# PRU_ICSS_0_MII_MDIO_local register map
Vendor: Texas Instruments
Peripheral module from a debugger description file (folder 66AK2G0x_66AK2G1x).
Registers are 32-bit, access not given, reset 0x0 unless marked. A register's access mark holds for its fields unless they carry their own. Offsets are as the file gives them; lines under a group give offsets from that group; [hi:lo] are bit positions; {n}, {i} and the like mark numbered series; 'fields as' and 'values as' point back to an identical list; <NAME> marks a mode.

## PRU_ICSS_0_MII_MDIO
0x00 PRUSS_MII_MDIO_VER ro reset not defined
  [31:0] REVISION — IP Revision.
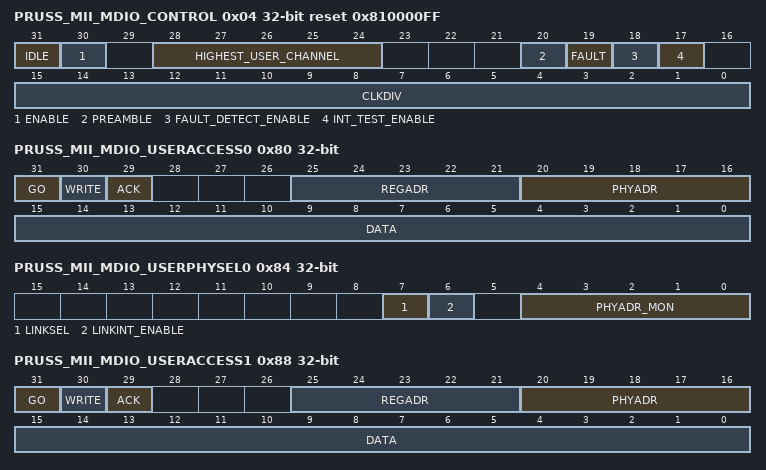
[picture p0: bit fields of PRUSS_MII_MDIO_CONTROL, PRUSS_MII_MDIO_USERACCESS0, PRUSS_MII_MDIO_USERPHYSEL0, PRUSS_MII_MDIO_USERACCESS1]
0x04 PRUSS_MII_MDIO_CONTROL reset 0x810000FF
  [31] IDLE ro — MDIO state machine IDLE. Set to 1 when the state machine is in the idle state.
  [30] ENABLE rw — Enable control.
  [28:24] HIGHEST_USER_CHANNEL ro — Highest user channel. This field specifies the highest useraccess channel that is available in the module and is currently set to 1. This implies that
  [20] PREAMBLE rw — Preamble disable. Writing a 1 to this bit disables this device from sending MDIO frame preambles.
  [19] FAULT — Fault indicator. This bit is set to 1 if the MDIO pins fail to read back what the device is driving onto them. This indicates a physical layer fault and the module state machine is reset. Writing a 1 to it clears this bit. (access RWr1Clr)
  [18] FAULT_DETECT_ENABLE rw — Fault detect enable. This bit has to be set to 1 to enable the physical layer fault detection.
  [17] INT_TEST_ENABLE rw — Interrupt test enable. This bit can be set to 1 to enable the host to set the userint and linkint bits for test purposes.
  [15:0] CLKDIV rw — Clock Divider. This field specifies the division ratio between CLK and the frequency of MDCLK. MDCLK is disabled when clkdiv is set to 0. MDCLK frequency = clk frequency/(clkdiv+1).
0x08 PRUSS_MII_MDIO_ALIVE
  [31:0] ALIVE — MDIO Alive bitfield. (access RWr1Clr)
0x0C PRUSS_MII_MDIO_LINK ro
  [31:0] LINK — MDIO Link state. This register is updated after a read of the Generic Status Register of a PHY. The bit is set if the PHY with the corresponding address has link and the PHY acknowledges the read transaction. The bit is reset if the PHY indicates it does not have link or fails to acknowledge the read transaction. Writes to the register have no effect. In addition, the status of the two PHYs specified in the
0x10 PRUSS_MII_MDIO_LINKINTRAW
  [1:0] LINKINTRAW — MDIO link change event, raw value. When asserted 1 , a bit indicates that there was an (access RWr1Clr)
0x14 PRUSS_MII_MDIO_LINKINTMASKED
  [1:0] LINKINTMASKED — MDIO link change interrupt, masked value. When asserted 1 , a bit indicates that there was an MDIO link change event (i.e. change in the MDIOLink register) corresponding to the PHY address in the MDIOUserPhySel register and the corresponding linkint_enable bit was set. linkintmasked[0] and linkintmasked[1] correspond to MDIOUserPhySel0 and MDIOUserPhysel1, respectively. Writing a 1 will clear the interrupt and writing 0 has no effect. If the int_test bit in the MDIOControl register is set, the host may set the linkint bits to a 1 . This mode may be used for test purposes. (access RWr1Clr)
0x20 PRUSS_MII_MDIO_USERINTRAW
  [1:0] USERINTRAW — Raw value of MDIO user command complete event for MDIOUserAccess1 through MDIOUserAccess0, respectively. When asserted 1 , a bit indicates that the previously scheduled PHY read or write command using that particular MDIOUserAccess register has completed. Writing a 1 will clear the event and writing 0 has no effect. . If the int_test bit in the MDIOControl register is set, the host may set the userintraw bits to a 1 . This mode may be used for test purposes. (access RWr1Clr)
0x24 PRUSS_MII_MDIO_USERINTMASKED
  [1:0] USERINTMASKED — Masked value of MDIO user command complete interrupt for MDIOUserAccess1 through MDIOUserAccess0, respectively. When asserted 1 , a bit indicates that the previously scheduled PHY read or write command using that particular MDIOUserAccess register has completed and the corresponding userintmaskset bit is set to 1 . . Writing a 1 will clear the interrupt and writing 0 has no effect. . If the int_test bit in the MDIOControl register is set, the host may set the userintmasked bits to a 1 . This mode may be used for test purposes. (access RWr1Clr)
0x28 PRUSS_MII_MDIO_USERINTMASKSET
  [1:0] USERINTMASKEDSET — MDIO user interrupt mask set for userintmasked[1:0], respectively. Writing a bit to 1 will enable MDIO user command complete interrupts for that particular MDIOUserAccess register. MDIO user interrupt for a particular MDIOUserAccess register is disabled if the corresponding bit is 0 . Writing a 0 to this register has no effect. (access RW1S)
0x2C PRUSS_MII_MDIO_USERINTMASKCLR
  [1:0] USERINTMASKEDCLR — MDIO user command complete interrupt mask clear for userintmasked[1:0], respectively. Writing a bit to 1 will disable further user command complete interrupts for that particular MDIOUserAccess register. Writing a 0 to this register has no effect. (access RWr1Clr)
0x80 PRUSS_MII_MDIO_USERACCESS0
  [31] GO — Go. Writing a 1 to this bit causes the MDIO state machine to perform an MDIO access when it is convenient for it to do so, this is not an instantaneous process. Writing a 0 to this bit has no effect. This bit is write able only if the MDIO state machine is enabled. This bit will self clear when the requested access has been completed. Any writes to the MDIOUserAccess0 register are blocked when the go bit is 1 . If byte access is being used, the go bit should be written last. (access RW1S)
  [30] WRITE rw — Write enable. Setting this bit to a 1 causes the MDIO transaction to be a register write, otherwise it is a register read.
  [29] ACK rw — Acknowledge. This bit is set if the PHY acknowledged the read transaction.
  [25:21] REGADR rw — Register address. This field specifies the PHY register to be accessed for this transaction.
  [20:16] PHYADR rw — PHY address. This field specifies the PHY to be accessed for this transaction.
  [15:0] DATA rw — User data. The data value read from or to be written to the specified PHY register.
0x84 PRUSS_MII_MDIO_USERPHYSEL0 access per field
  [7] LINKSEL rw — Link status determination select. Set to 1 to determine link status using the MLINK pin. Default value is 0 which implies that the link status is determined by the MDIO state machine.
  [6] LINKINT_ENABLE rw — Link change interrupt enable. Set to 1 to enable link change status interrupts for PHY address specified in phyadr_mon. Link change interrupts are disabled if this bit is set to 0 .
  [4:0] PHYADR_MON rw — PHY address whose link status is to be monitored.
0x88 PRUSS_MII_MDIO_USERACCESS1 access per field
  [31] GO rw — Go. Writing a 1 to this bit causes the MDIO state machine to perform an MDIO access when it is convenient for it to do so, this is not an instantaneous process. Writing a 0 to this bit has no effect. This bit is write able only if the MDIO state machine is enabled. This bit will self clear when the requested access has been completed. Any writes to the MDIOUserAccess0 register are blocked when the go bit is 1 . If byte access is being used, the go bit should be written last.
  [30] WRITE rw — Write enable. Setting this bit to a 1 causes the MDIO transaction to be a register write, otherwise it is a register read.
  [29] ACK rw — Acknowledge. This bit is set if the PHY acknowledged the read transaction.
  [25:21] REGADR rw — Register address. This field specifies the PHY register to be accessed for this transaction.
  [20:16] PHYADR rw — PHY address. This field specifies the PHY to be accessed for this transaction.
  [15:0] DATA rw — User data. The data value read from or to be written to the specified PHY register.
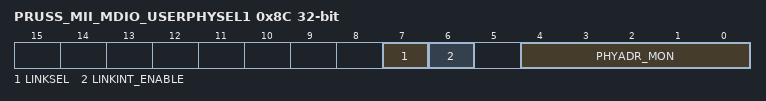
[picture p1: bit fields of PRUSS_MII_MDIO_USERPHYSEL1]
0x8C PRUSS_MII_MDIO_USERPHYSEL1 access per field
  fields as PRUSS_MII_MDIO_USERPHYSEL0
